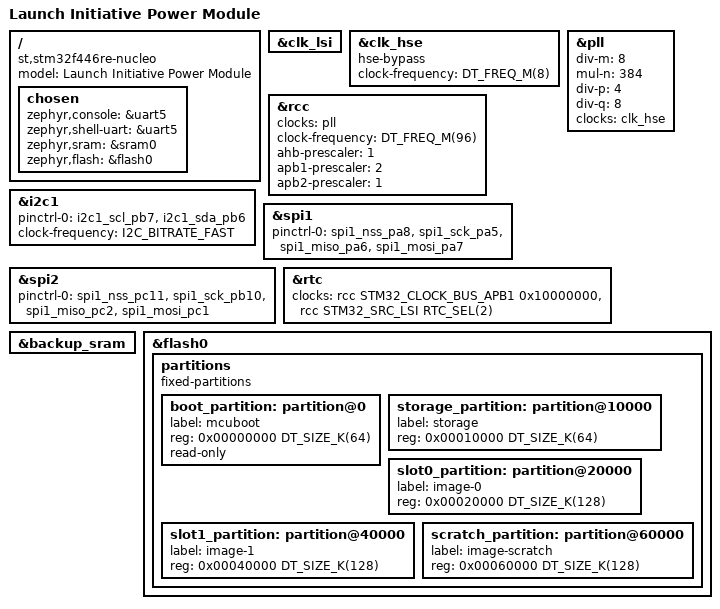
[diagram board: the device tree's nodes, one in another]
/*
 * Copyright (c) 2018 Philémon Jaermann
 *
 * SPDX-License-Identifier: Apache-2.0
 */

/dts-v1/;
#include <st/f4/stm32f446Xe.dtsi>
#include <st/f4/stm32f446r(c-e)tx-pinctrl.dtsi>
#include <zephyr/dt-bindings/input/input-event-codes.h>

/ {
	model = "Launch Initiative Power Module";
	compatible = "st,stm32f446re-nucleo";

	chosen {
		zephyr,console = &uart5;
		zephyr,shell-uart = &uart5;
		zephyr,sram = &sram0;
		zephyr,flash = &flash0;
	};

//	leds: leds {
//		compatible = "gpio-leds";
//		green_led_2: led_2 {
//			gpios = <&gpioa 5 GPIO_ACTIVE_HIGH>;
//			label = "User LD2";
//		};
//	};
//
//
//	aliases {
//		led0 = &green_led_2;
//	};
};

&clk_lsi {
	status = "okay";
};

&clk_hse {
	hse-bypass;
	clock-frequency = <DT_FREQ_M(8)>; /* STLink 8MHz clock */
	status = "okay";
};

&pll {
	div-m = <8>;
	mul-n = <384>;
	div-p = <4>;
	div-q = <8>;
	clocks = <&clk_hse>;
	status = "okay";
};

&rcc {
	clocks = <&pll>;
	clock-frequency = <DT_FREQ_M(96)>;
	ahb-prescaler = <1>;
	apb1-prescaler = <2>;
	apb2-prescaler = <1>;
};


&i2c1 {
	pinctrl-0 = <&i2c1_scl_pb7 &i2c1_sda_pb6>;
	pinctrl-names = "default";
	status = "okay";
	clock-frequency = <I2C_BITRATE_FAST>;
};

&spi1 {
	pinctrl-0 = <&spi1_nss_pa8 &spi1_sck_pa5
		     &spi1_miso_pa6 &spi1_mosi_pa7>;
	pinctrl-names = "default";
	status = "okay";
};

&spi2 {
	pinctrl-0 = <&spi1_nss_pc11 &spi1_sck_pb10
		     &spi1_miso_pc2 &spi1_mosi_pc1>;
	pinctrl-names = "default";
	status = "okay";
};

&rtc {
	clocks = <&rcc STM32_CLOCK_BUS_APB1 0x10000000>,
		 <&rcc STM32_SRC_LSI RTC_SEL(2)>;
	status = "okay";
};

&backup_sram {
	status = "okay";
};


&flash0 {

	partitions {
		compatible = "fixed-partitions";
		#address-cells = <1>;
		#size-cells = <1>;

		boot_partition: partition@0 {
			label = "mcuboot";
			reg = <0x00000000 DT_SIZE_K(64)>;
			read-only;
		};

		/*
		 * The flash starting at 0x00010000 and ending at
		 * 0x0001ffff (sectors 16-31) is reserved for use
		 * by the application.
		 */
		storage_partition: partition@10000 {
			label = "storage";
			reg = <0x00010000 DT_SIZE_K(64)>;
		};

		slot0_partition: partition@20000 {
			label = "image-0";
			reg = <0x00020000 DT_SIZE_K(128)>;
		};
		slot1_partition: partition@40000 {
			label = "image-1";
			reg = <0x00040000 DT_SIZE_K(128)>;
		};
		scratch_partition: partition@60000 {
			label = "image-scratch";
			reg = <0x00060000 DT_SIZE_K(128)>;
		};
	};
};
